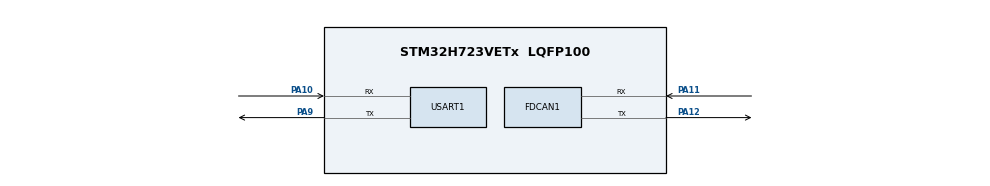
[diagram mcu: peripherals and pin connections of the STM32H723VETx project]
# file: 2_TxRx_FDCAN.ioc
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FDCAN1.CalculateBaudRateNominal=1000000
FDCAN1.CalculateTimeBitNominal=1000
FDCAN1.CalculateTimeQuantumNominal=200.0
FDCAN1.Mode=FDCAN_MODE_NORMAL
FDCAN1.NominalPrescaler=27
FDCAN1.RxFifo0ElmtsNbr=32
FDCAN1.StdFiltersNbr=1
FDCAN1.TxFifoQueueElmtsNbr=32
Mcu.Family=STM32H7
Mcu.Name=STM32H723VETx
Mcu.Package=LQFP100
NVIC.FDCAN1_IT0_IRQn=true\:0\:0\:false\:false\:true\:true\:true\:true
NVIC.PriorityGroup=NVIC_PRIORITYGROUP_4
PA10.Mode=Asynchronous
PA10.Signal=USART1_RX
PA11.Mode=FDCAN_Activate
PA11.Signal=FDCAN1_RX
PA12.Mode=FDCAN_Activate
PA12.Signal=FDCAN1_TX
PA13(JTMS/SWDIO).Mode=Serial_Wire
PA13(JTMS/SWDIO).Signal=DEBUG_JTMS-SWDIO
PA14(JTCK/SWCLK).Mode=Serial_Wire
PA14(JTCK/SWCLK).Signal=DEBUG_JTCK-SWCLK
PA9.Mode=Asynchronous
PA9.Signal=USART1_TX
PH0-OSC_IN.Mode=HSE-External-Oscillator
PH0-OSC_IN.Signal=RCC_OSC_IN
PH1-OSC_OUT.Mode=HSE-External-Oscillator
PH1-OSC_OUT.Signal=RCC_OSC_OUT
ProjectManager.HeapSize=0x200
ProjectManager.StackSize=0x400
ProjectManager.TargetToolchain=Makefile
RCC.ADCFreq_Value=16125000
RCC.APB1Freq_Value=135000000
RCC.APB2Freq_Value=135000000
RCC.APB3Freq_Value=135000000
RCC.APB4Freq_Value=135000000
RCC.CortexFreq_Value=540000000
RCC.D1PPRE=RCC_APB3_DIV2
RCC.D2PPRE1=RCC_APB1_DIV2
RCC.D2PPRE2=RCC_APB2_DIV2
RCC.D3PPRE=RCC_APB4_DIV2
RCC.DIVM1=1
RCC.DIVN1=67
RCC.DIVP1=1
RCC.DIVQ1=4
RCC.HCLKFreq_Value=270000000
RCC.HPRE=RCC_HCLK_DIV2
RCC.HSE_VALUE=8000000
RCC.PLLFRACN=4096
RCC.PLLSourceVirtual=RCC_PLLSOURCE_HSE
RCC.SYSCLKFreq_VALUE=540000000
RCC.SYSCLKSource=RCC_SYSCLKSOURCE_PLLCLK
RCC.USBFreq_Value=135000000
USART1.VirtualMode-Asynchronous=VM_ASYNC
board=custom

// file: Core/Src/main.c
/* USER CODE BEGIN Header */
/**
 ******************************************************************************
 * @file           : main.c
 * @brief          : Main program body
 ******************************************************************************
 * @attention
 *
 * Copyright (c) 2023 STMicroelectronics.
 * All rights reserved.
 *
 * This software is licensed under terms that can be found in the LICENSE file
 * in the root directory of this software component.
 * If no LICENSE file comes with this software, it is provided AS-IS.
 *
 ******************************************************************************
 */
/* USER CODE END Header */
#include "main.h"
#include "fdcan.h"
#include "usart.h"
#include "gpio.h"

/* USER CODE BEGIN Includes */
#include "DJI.h"
#include "wtr_can.h"
#include "Caculate.h"
#include <stdio.h>
/* USER CODE END Includes */

void SystemClock_Config(void);

int main(void)
{

    /* MCU Configuration--------------------------------------------------------*/

    /* Reset of all peripherals, Initializes the Flash interface and the Systick. */
    HAL_Init();

    /* Configure the system clock */
    SystemClock_Config();

    /* Initialize all configured peripherals */
    MX_GPIO_Init();
    MX_FDCAN1_Init();
    MX_USART1_UART_Init();
    /* USER CODE BEGIN 2 */
    fdcan1.FDCAN_Rx_Filter_Init();
    fdcan1.FDCAN_Start();
    fdcan1.FDCAN_Interrupt_Init();
    hDJI[0].motorType = M3508;
    DJI_Init();

    /* USER CODE END 2 */

    /* Infinite loop */
    while (1) {

        /* USER CODE BEGIN 3 */
        speedServo(100, &hDJI[0]);
        CanTransmit_DJI_1234(hDJI[0].speedPID.output, 0, 0, 0);
        HAL_Delay(2);
    }
    /* USER CODE END 3 */
}

void SystemClock_Config(void)
{
    RCC_OscInitTypeDef RCC_OscInitStruct = {0};
    RCC_ClkInitTypeDef RCC_ClkInitStruct = {0};

    /** Supply configuration update enable
     */
    HAL_PWREx_ConfigSupply(PWR_LDO_SUPPLY);

    /** Configure the main internal regulator output voltage
     */
    __HAL_PWR_VOLTAGESCALING_CONFIG(PWR_REGULATOR_VOLTAGE_SCALE0);

    while (!__HAL_PWR_GET_FLAG(PWR_FLAG_VOSRDY)) {}

    /** Initializes the RCC Oscillators according to the specified parameters
     * in the RCC_OscInitTypeDef structure.
     */
    RCC_OscInitStruct.OscillatorType = RCC_OSCILLATORTYPE_HSE;
    RCC_OscInitStruct.HSEState       = RCC_HSE_ON;
    RCC_OscInitStruct.PLL.PLLState   = RCC_PLL_ON;
    RCC_OscInitStruct.PLL.PLLSource  = RCC_PLLSOURCE_HSE;
    RCC_OscInitStruct.PLL.PLLM       = 1;
    RCC_OscInitStruct.PLL.PLLN       = 67;
    RCC_OscInitStruct.PLL.PLLP       = 1;
    RCC_OscInitStruct.PLL.PLLQ       = 4;
    RCC_OscInitStruct.PLL.PLLR       = 2;
    RCC_OscInitStruct.PLL.PLLRGE     = RCC_PLL1VCIRANGE_3;
    RCC_OscInitStruct.PLL.PLLVCOSEL  = RCC_PLL1VCOWIDE;
    RCC_OscInitStruct.PLL.PLLFRACN   = 4096;
    if (HAL_RCC_OscConfig(&RCC_OscInitStruct) != HAL_OK) {
        Error_Handler();
    }

    /** Initializes the CPU, AHB and APB buses clocks
     */
    RCC_ClkInitStruct.ClockType      = RCC_CLOCKTYPE_HCLK | RCC_CLOCKTYPE_SYSCLK | RCC_CLOCKTYPE_PCLK1 | RCC_CLOCKTYPE_PCLK2 | RCC_CLOCKTYPE_D3PCLK1 | RCC_CLOCKTYPE_D1PCLK1;
    RCC_ClkInitStruct.SYSCLKSource   = RCC_SYSCLKSOURCE_PLLCLK;
    RCC_ClkInitStruct.SYSCLKDivider  = RCC_SYSCLK_DIV1;
    RCC_ClkInitStruct.AHBCLKDivider  = RCC_HCLK_DIV2;
    RCC_ClkInitStruct.APB3CLKDivider = RCC_APB3_DIV2;
    RCC_ClkInitStruct.APB1CLKDivider = RCC_APB1_DIV2;
    RCC_ClkInitStruct.APB2CLKDivider = RCC_APB2_DIV2;
    RCC_ClkInitStruct.APB4CLKDivider = RCC_APB4_DIV2;

    if (HAL_RCC_ClockConfig(&RCC_ClkInitStruct, FLASH_LATENCY_3) != HAL_OK) {
        Error_Handler();
    }
}

void Error_Handler(void)
{
    __disable_irq();
    while (1) {
    }
}
